AUTOSAR XML (schema 4-2-2)
package /STELLANTIS/EPT/COMSWCs
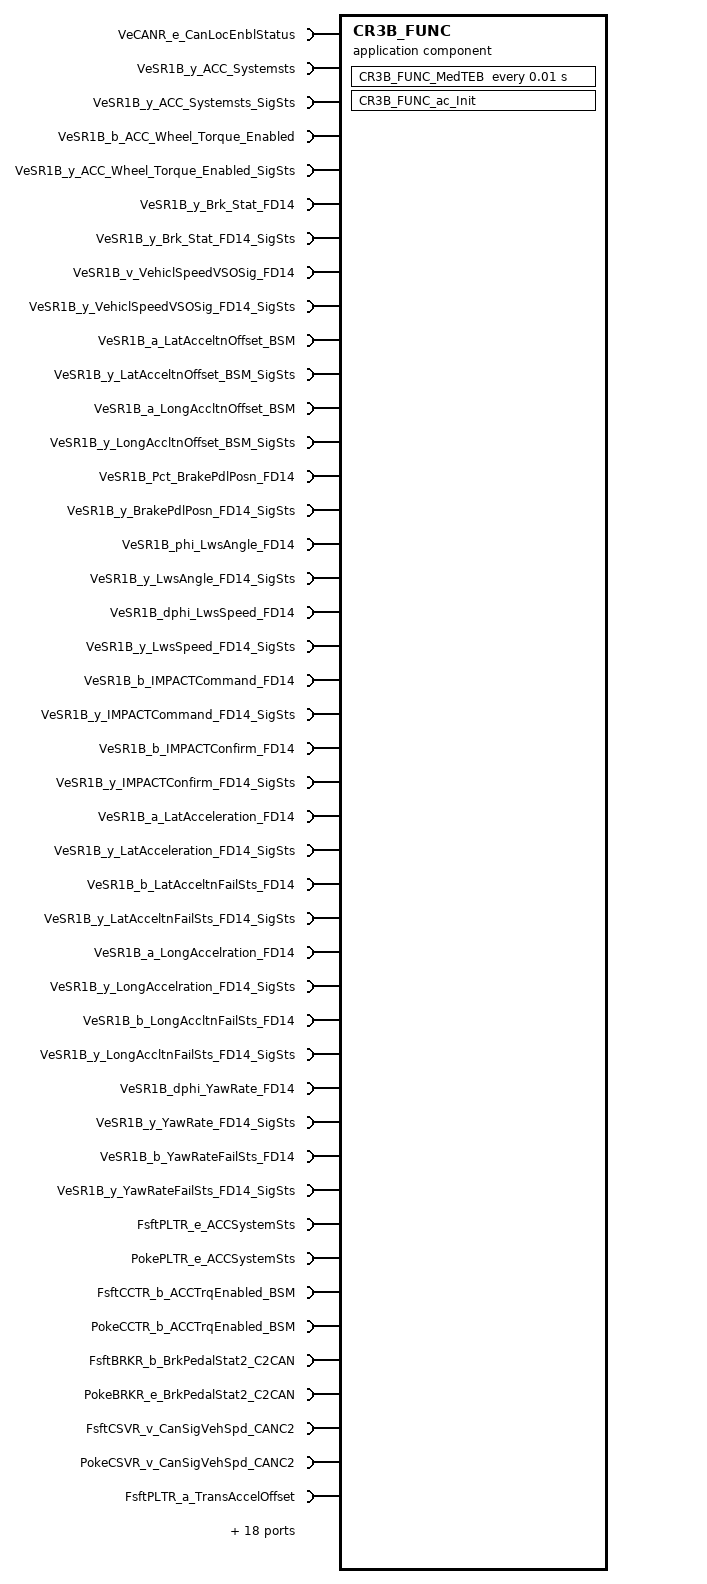
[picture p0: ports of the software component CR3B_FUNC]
  application sw component type CR3B_FUNC
    62 x require port:
      VeCANR_e_CanLocEnblStatus: nonqueued-receiver-com-spec{data-element=VeCANR_e_CanLocEnblStatus, init-value=0}, required-interface=VeCANR_e_CanLocEnblStatus
      VeSR1B_y_ACC_Systemsts: nonqueued-receiver-com-spec{data-element=Value, handle-never-received=true, init-value=0}, required-interface=VeSR1B_y_ACC_Systemsts
      VeSR1B_y_ACC_Systemsts_SigSts: nonqueued-receiver-com-spec{data-element=Value, init-value=0}, required-interface=VeSR1B_y_ACC_Systemsts_SigSts
      VeSR1B_b_ACC_Wheel_Torque_Enabled: nonqueued-receiver-com-spec{data-element=Value, handle-never-received=true, init-value=0}, required-interface=VeSR1B_b_ACC_Wheel_Torque_Enabled
      VeSR1B_y_ACC_Wheel_Torque_Enabled_SigSts: nonqueued-receiver-com-spec{data-element=Value, init-value=0}, required-interface=VeSR1B_y_ACC_Wheel_Torque_Enabled_SigSts
      VeSR1B_y_Brk_Stat_FD14: nonqueued-receiver-com-spec{data-element=Value, handle-never-received=true, init-value=0}, required-interface=VeSR1B_y_Brk_Stat_FD14
      VeSR1B_y_Brk_Stat_FD14_SigSts: nonqueued-receiver-com-spec{data-element=Value, init-value=0}, required-interface=VeSR1B_y_Brk_Stat_FD14_SigSts
      VeSR1B_v_VehiclSpeedVSOSig_FD14: nonqueued-receiver-com-spec{data-element=Value, handle-never-received=true, init-value=0}, required-interface=VeSR1B_v_VehiclSpeedVSOSig_FD14
      VeSR1B_y_VehiclSpeedVSOSig_FD14_SigSts: nonqueued-receiver-com-spec{data-element=Value, init-value=0}, required-interface=VeSR1B_y_VehiclSpeedVSOSig_FD14_SigSts
      VeSR1B_a_LatAcceltnOffset_BSM: nonqueued-receiver-com-spec{data-element=Value, handle-never-received=true, init-value=0}, required-interface=VeSR1B_a_LatAcceltnOffset_BSM
      VeSR1B_y_LatAcceltnOffset_BSM_SigSts: nonqueued-receiver-com-spec{data-element=Value, init-value=0}, required-interface=VeSR1B_y_LatAcceltnOffset_BSM_SigSts
      VeSR1B_a_LongAccltnOffset_BSM: nonqueued-receiver-com-spec{data-element=Value, handle-never-received=true, init-value=0}, required-interface=VeSR1B_a_LongAccltnOffset_BSM
      VeSR1B_y_LongAccltnOffset_BSM_SigSts: nonqueued-receiver-com-spec{data-element=Value, init-value=0}, required-interface=VeSR1B_y_LongAccltnOffset_BSM_SigSts
      VeSR1B_Pct_BrakePdlPosn_FD14: nonqueued-receiver-com-spec{data-element=Value, handle-never-received=true, init-value=0}, required-interface=VeSR1B_Pct_BrakePdlPosn_FD14
      VeSR1B_y_BrakePdlPosn_FD14_SigSts: nonqueued-receiver-com-spec{data-element=Value, init-value=0}, required-interface=VeSR1B_y_BrakePdlPosn_FD14_SigSts
      VeSR1B_phi_LwsAngle_FD14: nonqueued-receiver-com-spec{data-element=Value, handle-never-received=true, init-value=0}, required-interface=VeSR1B_phi_LwsAngle_FD14
      VeSR1B_y_LwsAngle_FD14_SigSts: nonqueued-receiver-com-spec{data-element=Value, init-value=0}, required-interface=VeSR1B_y_LwsAngle_FD14_SigSts
      VeSR1B_dphi_LwsSpeed_FD14: nonqueued-receiver-com-spec{data-element=Value, handle-never-received=true, init-value=0}, required-interface=VeSR1B_dphi_LwsSpeed_FD14
      VeSR1B_y_LwsSpeed_FD14_SigSts: nonqueued-receiver-com-spec{data-element=Value, init-value=0}, required-interface=VeSR1B_y_LwsSpeed_FD14_SigSts
      VeSR1B_b_IMPACTCommand_FD14: nonqueued-receiver-com-spec{data-element=Value, handle-never-received=true, init-value=0}, required-interface=VeSR1B_b_IMPACTCommand_FD14
      VeSR1B_y_IMPACTCommand_FD14_SigSts: nonqueued-receiver-com-spec{data-element=Value, init-value=0}, required-interface=VeSR1B_y_IMPACTCommand_FD14_SigSts
      VeSR1B_b_IMPACTConfirm_FD14: nonqueued-receiver-com-spec{data-element=Value, handle-never-received=true, init-value=0}, required-interface=VeSR1B_b_IMPACTConfirm_FD14
      VeSR1B_y_IMPACTConfirm_FD14_SigSts: nonqueued-receiver-com-spec{data-element=Value, init-value=0}, required-interface=VeSR1B_y_IMPACTConfirm_FD14_SigSts
      VeSR1B_a_LatAcceleration_FD14: nonqueued-receiver-com-spec{data-element=Value, handle-never-received=true, init-value=0}, required-interface=VeSR1B_a_LatAcceleration_FD14
      VeSR1B_y_LatAcceleration_FD14_SigSts: nonqueued-receiver-com-spec{data-element=Value, init-value=0}, required-interface=VeSR1B_y_LatAcceleration_FD14_SigSts
      VeSR1B_b_LatAcceltnFailSts_FD14: nonqueued-receiver-com-spec{data-element=Value, handle-never-received=true, init-value=0}, required-interface=VeSR1B_b_LatAcceltnFailSts_FD14
      VeSR1B_y_LatAcceltnFailSts_FD14_SigSts: nonqueued-receiver-com-spec{data-element=Value, init-value=0}, required-interface=VeSR1B_y_LatAcceltnFailSts_FD14_SigSts
      VeSR1B_a_LongAccelration_FD14: nonqueued-receiver-com-spec{data-element=Value, handle-never-received=true, init-value=0}, required-interface=VeSR1B_a_LongAccelration_FD14
      VeSR1B_y_LongAccelration_FD14_SigSts: nonqueued-receiver-com-spec{data-element=Value, init-value=0}, required-interface=VeSR1B_y_LongAccelration_FD14_SigSts
      VeSR1B_b_LongAccltnFailSts_FD14: nonqueued-receiver-com-spec{data-element=Value, handle-never-received=true, init-value=0}, required-interface=VeSR1B_b_LongAccltnFailSts_FD14
      VeSR1B_y_LongAccltnFailSts_FD14_SigSts: nonqueued-receiver-com-spec{data-element=Value, init-value=0}, required-interface=VeSR1B_y_LongAccltnFailSts_FD14_SigSts
      VeSR1B_dphi_YawRate_FD14: nonqueued-receiver-com-spec{data-element=Value, handle-never-received=true, init-value=0}, required-interface=VeSR1B_dphi_YawRate_FD14
      VeSR1B_y_YawRate_FD14_SigSts: nonqueued-receiver-com-spec{data-element=Value, init-value=0}, required-interface=VeSR1B_y_YawRate_FD14_SigSts
      VeSR1B_b_YawRateFailSts_FD14: nonqueued-receiver-com-spec{data-element=Value, handle-never-received=true, init-value=0}, required-interface=VeSR1B_b_YawRateFailSts_FD14
      VeSR1B_y_YawRateFailSts_FD14_SigSts: nonqueued-receiver-com-spec{data-element=Value, init-value=0}, required-interface=VeSR1B_y_YawRateFailSts_FD14_SigSts
      FsftPLTR_e_ACCSystemSts: client-com-spec=FsftPLTR_e_ACCSystemSts, required-interface=FsftPLTR_e_ACCSystemSts
      PokePLTR_e_ACCSystemSts: client-com-spec=PokePLTR_e_ACCSystemSts, required-interface=PokePLTR_e_ACCSystemSts
      FsftCCTR_b_ACCTrqEnabled_BSM: client-com-spec=FsftCCTR_b_ACCTrqEnabled_BSM, required-interface=FsftCCTR_b_ACCTrqEnabled_BSM
      PokeCCTR_b_ACCTrqEnabled_BSM: client-com-spec=PokeCCTR_b_ACCTrqEnabled_BSM, required-interface=PokeCCTR_b_ACCTrqEnabled_BSM
      FsftBRKR_b_BrkPedalStat2_C2CAN: client-com-spec=FsftBRKR_b_BrkPedalStat2_C2CAN, required-interface=FsftBRKR_b_BrkPedalStat2_C2CAN
      PokeBRKR_e_BrkPedalStat2_C2CAN: client-com-spec=PokeBRKR_e_BrkPedalStat2_C2CAN, required-interface=PokeBRKR_e_BrkPedalStat2_C2CAN
      FsftCSVR_v_CanSigVehSpd_CANC2: client-com-spec=FsftCSVR_v_CanSigVehSpd_CANC2, required-interface=FsftCSVR_v_CanSigVehSpd_CANC2
      PokeCSVR_v_CanSigVehSpd_CANC2: client-com-spec=PokeCSVR_v_CanSigVehSpd_CANC2, required-interface=PokeCSVR_v_CanSigVehSpd_CANC2
      FsftPLTR_a_TransAccelOffset: client-com-spec=FsftPLTR_a_TransAccelOffset, required-interface=FsftPLTR_a_TransAccelOffset
      PokePLTR_a_TransAccelOffset: client-com-spec=PokePLTR_a_TransAccelOffset, required-interface=PokePLTR_a_TransAccelOffset
      FsftPLTR_a_LongAccelOffset: client-com-spec=FsftPLTR_a_LongAccelOffset, required-interface=FsftPLTR_a_LongAccelOffset
      PokePLTR_a_LongAccelOffset: client-com-spec=PokePLTR_a_LongAccelOffset, required-interface=PokePLTR_a_LongAccelOffset
      FsftBRKR_b_BrkTravelSts_C2CAN: client-com-spec=FsftBRKR_b_BrkTravelSts_C2CAN, required-interface=FsftBRKR_b_BrkTravelSts_C2CAN
      PokeBRKR_Pct_BrkTravelSt_C2CAN: client-com-spec=PokeBRKR_Pct_BrkTravelSt_C2CAN, required-interface=PokeBRKR_Pct_BrkTravelSt_C2CAN
      FsftPLTR_phi_LwsAngle: client-com-spec=FsftPLTR_phi_LwsAngle, required-interface=FsftPLTR_phi_LwsAngle
      PokePLTR_phi_LwsAngle: client-com-spec=PokePLTR_phi_LwsAngle, required-interface=PokePLTR_phi_LwsAngle
      PokePLTR_dphi_LwsSpeed: client-com-spec=PokePLTR_dphi_LwsSpeed, required-interface=PokePLTR_dphi_LwsSpeed
      FsftIMPR_b_VehImpactDetected: client-com-spec=FsftIMPR_b_VehImpactDetected, required-interface=FsftIMPR_b_VehImpactDetected
      PokeIMPR_b_VehImpactDetected: client-com-spec=PokeIMPR_b_VehImpactDetected, required-interface=PokeIMPR_b_VehImpactDetected
      FsftIMPR_b_ImpactToggle: client-com-spec=FsftIMPR_b_ImpactToggle, required-interface=FsftIMPR_b_ImpactToggle
      PokeIMPR_b_ImpactToggle: client-com-spec=PokeIMPR_b_ImpactToggle, required-interface=PokeIMPR_b_ImpactToggle
      PokePLTR_a_LatAccel_ORC: client-com-spec=PokePLTR_a_LatAccel_ORC, required-interface=PokePLTR_a_LatAccel_ORC
      PokePLTR_b_LatAccelFailSts_ORC: client-com-spec=PokePLTR_b_LatAccelFailSts_ORC, required-interface=PokePLTR_b_LatAccelFailSts_ORC
      PokePLTR_a_LongAccel_ORC: client-com-spec=PokePLTR_a_LongAccel_ORC, required-interface=PokePLTR_a_LongAccel_ORC
      PokePLTR_b_LongAccelFailSts_ORC: client-com-spec=PokePLTR_b_LongAccelFailSts_ORC, required-interface=PokePLTR_b_LongAccelFailSts_ORC
      PokePLTR_dphi_YawRate_ORC: client-com-spec=PokePLTR_dphi_YawRate_ORC, required-interface=PokePLTR_dphi_YawRate_ORC
      PokePLTR_b_YawRateFailSts_ORC: client-com-spec=PokePLTR_b_YawRateFailSts_ORC, required-interface=PokePLTR_b_YawRateFailSts_ORC
    behavior IB_CR3B_FUNC: data-type-mapping=msADTtoIDTMapping, handle-termination-and-restart=NO-SUPPORT
      timing event Event_MedTEB: start-on-event=CR3B_FUNC_MedTEB, period=0.01
      init event Event_CR3B_FUNC_ac_Init: start-on-event=CR3B_FUNC_ac_Init
      runnable CR3B_FUNC_ac_Init
      runnable CR3B_FUNC_MedTEB
        data-receive-point-by-arguments:
          35 x access:
            IN_VeCANR_e_CanLocEnblStatus_VeCANR_e_CanLocEnblStatus: accessed-variable=VeCANR_e_CanLocEnblStatus.VeCANR_e_CanLocEnblStatus
            IN_VeSR1B_Pct_BrakePdlPosn_FD14_Value: accessed-variable=VeSR1B_Pct_BrakePdlPosn_FD14.Value
            IN_VeSR1B_a_LatAcceleration_FD14_Value: accessed-variable=VeSR1B_a_LatAcceleration_FD14.Value
            IN_VeSR1B_a_LatAcceltnOffset_BSM_Value: accessed-variable=VeSR1B_a_LatAcceltnOffset_BSM.Value
            IN_VeSR1B_a_LongAccelration_FD14_Value: accessed-variable=VeSR1B_a_LongAccelration_FD14.Value
            IN_VeSR1B_a_LongAccltnOffset_BSM_Value: accessed-variable=VeSR1B_a_LongAccltnOffset_BSM.Value
            IN_VeSR1B_b_ACC_Wheel_Torque_Enabled_Value: accessed-variable=VeSR1B_b_ACC_Wheel_Torque_Enabled.Value
            IN_VeSR1B_b_IMPACTCommand_FD14_Value: accessed-variable=VeSR1B_b_IMPACTCommand_FD14.Value
            IN_VeSR1B_b_IMPACTConfirm_FD14_Value: accessed-variable=VeSR1B_b_IMPACTConfirm_FD14.Value
            IN_VeSR1B_b_LatAcceltnFailSts_FD14_Value: accessed-variable=VeSR1B_b_LatAcceltnFailSts_FD14.Value
            IN_VeSR1B_b_LongAccltnFailSts_FD14_Value: accessed-variable=VeSR1B_b_LongAccltnFailSts_FD14.Value
            IN_VeSR1B_b_YawRateFailSts_FD14_Value: accessed-variable=VeSR1B_b_YawRateFailSts_FD14.Value
            IN_VeSR1B_dphi_LwsSpeed_FD14_Value: accessed-variable=VeSR1B_dphi_LwsSpeed_FD14.Value
            IN_VeSR1B_dphi_YawRate_FD14_Value: accessed-variable=VeSR1B_dphi_YawRate_FD14.Value
            IN_VeSR1B_phi_LwsAngle_FD14_Value: accessed-variable=VeSR1B_phi_LwsAngle_FD14.Value
            IN_VeSR1B_v_VehiclSpeedVSOSig_FD14_Value: accessed-variable=VeSR1B_v_VehiclSpeedVSOSig_FD14.Value
            IN_VeSR1B_y_ACC_Systemsts_Value: accessed-variable=VeSR1B_y_ACC_Systemsts.Value
            IN_VeSR1B_y_ACC_Systemsts_SigSts_Value: accessed-variable=VeSR1B_y_ACC_Systemsts_SigSts.Value
            IN_VeSR1B_y_ACC_Wheel_Torque_Enabled_SigSts_Value: accessed-variable=VeSR1B_y_ACC_Wheel_Torque_Enabled_SigSts.Value
            IN_VeSR1B_y_BrakePdlPosn_FD14_SigSts_Value: accessed-variable=VeSR1B_y_BrakePdlPosn_FD14_SigSts.Value
            IN_VeSR1B_y_Brk_Stat_FD14_Value: accessed-variable=VeSR1B_y_Brk_Stat_FD14.Value
            IN_VeSR1B_y_Brk_Stat_FD14_SigSts_Value: accessed-variable=VeSR1B_y_Brk_Stat_FD14_SigSts.Value
            IN_VeSR1B_y_IMPACTCommand_FD14_SigSts_Value: accessed-variable=VeSR1B_y_IMPACTCommand_FD14_SigSts.Value
            IN_VeSR1B_y_IMPACTConfirm_FD14_SigSts_Value: accessed-variable=VeSR1B_y_IMPACTConfirm_FD14_SigSts.Value
            IN_VeSR1B_y_LatAcceleration_FD14_SigSts_Value: accessed-variable=VeSR1B_y_LatAcceleration_FD14_SigSts.Value
            IN_VeSR1B_y_LatAcceltnFailSts_FD14_SigSts_Value: accessed-variable=VeSR1B_y_LatAcceltnFailSts_FD14_SigSts.Value
            IN_VeSR1B_y_LatAcceltnOffset_BSM_SigSts_Value: accessed-variable=VeSR1B_y_LatAcceltnOffset_BSM_SigSts.Value
            IN_VeSR1B_y_LongAccelration_FD14_SigSts_Value: accessed-variable=VeSR1B_y_LongAccelration_FD14_SigSts.Value
            IN_VeSR1B_y_LongAccltnFailSts_FD14_SigSts_Value: accessed-variable=VeSR1B_y_LongAccltnFailSts_FD14_SigSts.Value
            IN_VeSR1B_y_LongAccltnOffset_BSM_SigSts_Value: accessed-variable=VeSR1B_y_LongAccltnOffset_BSM_SigSts.Value
            IN_VeSR1B_y_LwsAngle_FD14_SigSts_Value: accessed-variable=VeSR1B_y_LwsAngle_FD14_SigSts.Value
            IN_VeSR1B_y_LwsSpeed_FD14_SigSts_Value: accessed-variable=VeSR1B_y_LwsSpeed_FD14_SigSts.Value
            IN_VeSR1B_y_VehiclSpeedVSOSig_FD14_SigSts_Value: accessed-variable=VeSR1B_y_VehiclSpeedVSOSig_FD14_SigSts.Value
            IN_VeSR1B_y_YawRateFailSts_FD14_SigSts_Value: accessed-variable=VeSR1B_y_YawRateFailSts_FD14_SigSts.Value
            IN_VeSR1B_y_YawRate_FD14_SigSts_Value: accessed-variable=VeSR1B_y_YawRate_FD14_SigSts.Value
        27 x sync call, all with timeout=1E-06:
          SC_FsftBRKR_b_BrkPedalStat2_C2CAN_FsftBRKR_b_BrkPedalStat2_C2CAN: operation=FsftBRKR_b_BrkPedalStat2_C2CAN.FsftBRKR_b_BrkPedalStat2_C2CAN
          SC_FsftBRKR_b_BrkTravelSts_C2CAN_FsftBRKR_b_BrkTravelSts_C2CAN: operation=FsftBRKR_b_BrkTravelSts_C2CAN.FsftBRKR_b_BrkTravelSts_C2CAN
          SC_FsftCCTR_b_ACCTrqEnabled_BSM_FsftCCTR_b_ACCTrqEnabled_BSM: operation=FsftCCTR_b_ACCTrqEnabled_BSM.FsftCCTR_b_ACCTrqEnabled_BSM
          SC_FsftCSVR_v_CanSigVehSpd_CANC2_FsftCSVR_v_CanSigVehSpd_CANC2: operation=FsftCSVR_v_CanSigVehSpd_CANC2.FsftCSVR_v_CanSigVehSpd_CANC2
          SC_FsftIMPR_b_ImpactToggle_FsftIMPR_b_ImpactToggle: operation=FsftIMPR_b_ImpactToggle.FsftIMPR_b_ImpactToggle
          SC_FsftIMPR_b_VehImpactDetected_FsftIMPR_b_VehImpactDetected: operation=FsftIMPR_b_VehImpactDetected.FsftIMPR_b_VehImpactDetected
          SC_FsftPLTR_a_LongAccelOffset_FsftPLTR_a_LongAccelOffset: operation=FsftPLTR_a_LongAccelOffset.FsftPLTR_a_LongAccelOffset
          SC_FsftPLTR_a_TransAccelOffset_FsftPLTR_a_TransAccelOffset: operation=FsftPLTR_a_TransAccelOffset.FsftPLTR_a_TransAccelOffset
          SC_FsftPLTR_e_ACCSystemSts_FsftPLTR_e_ACCSystemSts: operation=FsftPLTR_e_ACCSystemSts.FsftPLTR_e_ACCSystemSts
          SC_FsftPLTR_phi_LwsAngle_FsftPLTR_phi_LwsAngle: operation=FsftPLTR_phi_LwsAngle.FsftPLTR_phi_LwsAngle
          SC_PokeBRKR_Pct_BrkTravelSt_C2CAN_PokeBRKR_Pct_BrkTravelSt_C2CAN: operation=PokeBRKR_Pct_BrkTravelSt_C2CAN.PokeBRKR_Pct_BrkTravelSt_C2CAN
          SC_PokeBRKR_e_BrkPedalStat2_C2CAN_PokeBRKR_e_BrkPedalStat2_C2CAN: operation=PokeBRKR_e_BrkPedalStat2_C2CAN.PokeBRKR_e_BrkPedalStat2_C2CAN
          SC_PokeCCTR_b_ACCTrqEnabled_BSM_PokeCCTR_b_ACCTrqEnabled_BSM: operation=PokeCCTR_b_ACCTrqEnabled_BSM.PokeCCTR_b_ACCTrqEnabled_BSM
          SC_PokeCSVR_v_CanSigVehSpd_CANC2_PokeCSVR_v_CanSigVehSpd_CANC2: operation=PokeCSVR_v_CanSigVehSpd_CANC2.PokeCSVR_v_CanSigVehSpd_CANC2
          SC_PokeIMPR_b_ImpactToggle_PokeIMPR_b_ImpactToggle: operation=PokeIMPR_b_ImpactToggle.PokeIMPR_b_ImpactToggle
          SC_PokeIMPR_b_VehImpactDetected_PokeIMPR_b_VehImpactDetected: operation=PokeIMPR_b_VehImpactDetected.PokeIMPR_b_VehImpactDetected
          SC_PokePLTR_a_LatAccel_ORC_PokePLTR_a_LatAccel_ORC: operation=PokePLTR_a_LatAccel_ORC.PokePLTR_a_LatAccel_ORC
          SC_PokePLTR_a_LongAccelOffset_PokePLTR_a_LongAccelOffset: operation=PokePLTR_a_LongAccelOffset.PokePLTR_a_LongAccelOffset
          SC_PokePLTR_a_LongAccel_ORC_PokePLTR_a_LongAccel_ORC: operation=PokePLTR_a_LongAccel_ORC.PokePLTR_a_LongAccel_ORC
          SC_PokePLTR_a_TransAccelOffset_PokePLTR_a_TransAccelOffset: operation=PokePLTR_a_TransAccelOffset.PokePLTR_a_TransAccelOffset
          SC_PokePLTR_b_LatAccelFailSts_ORC_PokePLTR_b_LatAccelFailSts_ORC: operation=PokePLTR_b_LatAccelFailSts_ORC.PokePLTR_b_LatAccelFailSts_ORC
          SC_PokePLTR_b_LongAccelFailSts_ORC_PokePLTR_b_LongAccelFailSts_ORC: operation=PokePLTR_b_LongAccelFailSts_ORC.PokePLTR_b_LongAccelFailSts_ORC
          SC_PokePLTR_b_YawRateFailSts_ORC_PokePLTR_b_YawRateFailSts_ORC: operation=PokePLTR_b_YawRateFailSts_ORC.PokePLTR_b_YawRateFailSts_ORC
          SC_PokePLTR_dphi_LwsSpeed_PokePLTR_dphi_LwsSpeed: operation=PokePLTR_dphi_LwsSpeed.PokePLTR_dphi_LwsSpeed
          SC_PokePLTR_dphi_YawRate_ORC_PokePLTR_dphi_YawRate_ORC: operation=PokePLTR_dphi_YawRate_ORC.PokePLTR_dphi_YawRate_ORC
          SC_PokePLTR_e_ACCSystemSts_PokePLTR_e_ACCSystemSts: operation=PokePLTR_e_ACCSystemSts.PokePLTR_e_ACCSystemSts
          SC_PokePLTR_phi_LwsAngle_PokePLTR_phi_LwsAngle: operation=PokePLTR_phi_LwsAngle.PokePLTR_phi_LwsAngle
      4 x variation point proxy, all with category=CONDITION, condition-access=0:
        VrntCR3B_THASTAT
        VrntCR3B_THASpeedLimit
        VrntCR3B_TRSCSTAT
        VrntCR3B_TRSCSpeedLimitReq
